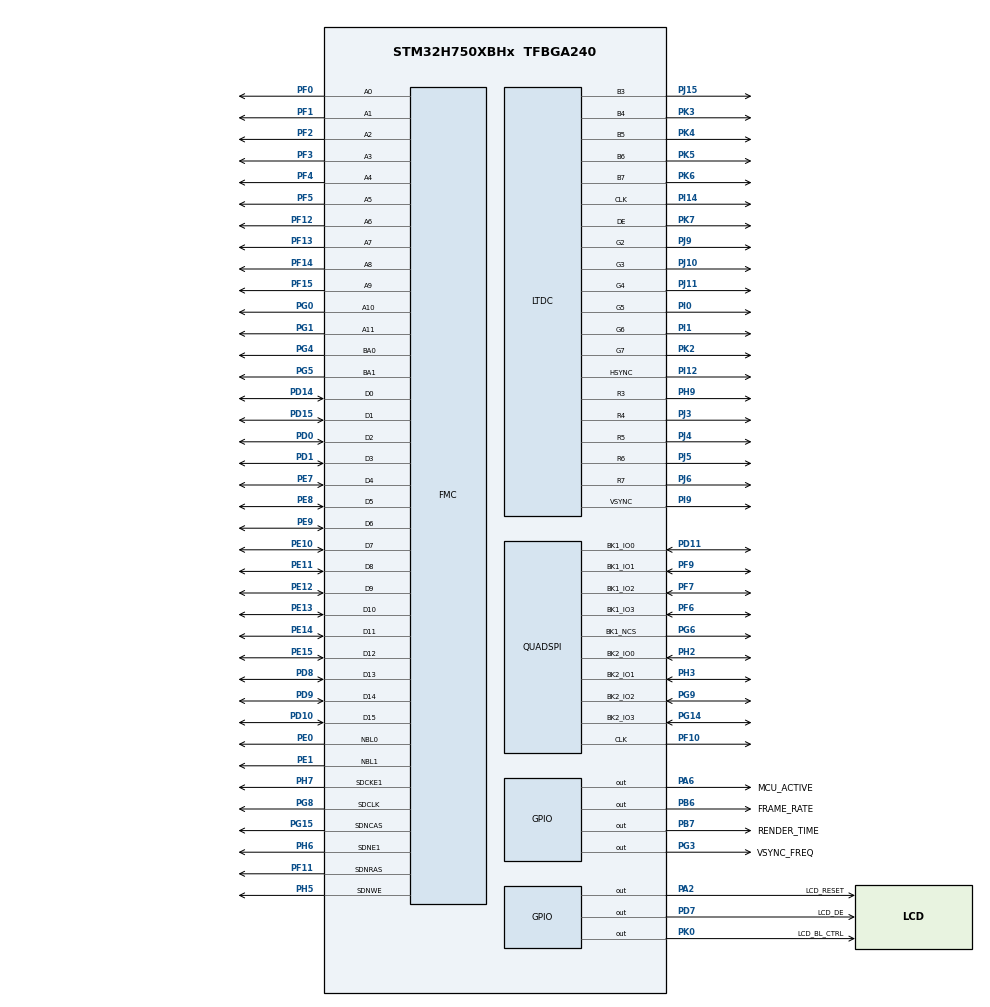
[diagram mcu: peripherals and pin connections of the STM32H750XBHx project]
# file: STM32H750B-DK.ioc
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CORTEX_M7.AccessPermission-Cortex_Memory_Protection_Unit_Region0_Settings=MPU_REGION_FULL_ACCESS
CORTEX_M7.AccessPermission-Cortex_Memory_Protection_Unit_Region1_Settings=MPU_REGION_NO_ACCESS
CORTEX_M7.AccessPermission-Cortex_Memory_Protection_Unit_Region2_Settings=MPU_REGION_FULL_ACCESS
CORTEX_M7.AccessPermission-Cortex_Memory_Protection_Unit_Region4_Settings=MPU_REGION_FULL_ACCESS
CORTEX_M7.BaseAddress-Cortex_Memory_Protection_Unit_Region0_Settings=0x24000000
CORTEX_M7.BaseAddress-Cortex_Memory_Protection_Unit_Region1_Settings=0x90000000
CORTEX_M7.BaseAddress-Cortex_Memory_Protection_Unit_Region2_Settings=0x90000000
CORTEX_M7.BaseAddress-Cortex_Memory_Protection_Unit_Region3_Settings=0xD0000000
CORTEX_M7.BaseAddress-Cortex_Memory_Protection_Unit_Region4_Settings=0xD0000000
CORTEX_M7.CPU_DCache=Enabled
CORTEX_M7.CPU_ICache=Enabled
CORTEX_M7.DisableExec-Cortex_Memory_Protection_Unit_Region0_Settings=MPU_INSTRUCTION_ACCESS_DISABLE
CORTEX_M7.DisableExec-Cortex_Memory_Protection_Unit_Region1_Settings=MPU_INSTRUCTION_ACCESS_DISABLE
CORTEX_M7.DisableExec-Cortex_Memory_Protection_Unit_Region2_Settings=MPU_INSTRUCTION_ACCESS_ENABLE
CORTEX_M7.DisableExec-Cortex_Memory_Protection_Unit_Region3_Settings=MPU_INSTRUCTION_ACCESS_DISABLE
CORTEX_M7.DisableExec-Cortex_Memory_Protection_Unit_Region4_Settings=MPU_INSTRUCTION_ACCESS_DISABLE
CORTEX_M7.Enable-Cortex_Memory_Protection_Unit_Region0_Settings=MPU_REGION_ENABLE
CORTEX_M7.Enable-Cortex_Memory_Protection_Unit_Region1_Settings=MPU_REGION_ENABLE
CORTEX_M7.Enable-Cortex_Memory_Protection_Unit_Region2_Settings=MPU_REGION_ENABLE
CORTEX_M7.Enable-Cortex_Memory_Protection_Unit_Region3_Settings=MPU_REGION_ENABLE
CORTEX_M7.Enable-Cortex_Memory_Protection_Unit_Region4_Settings=MPU_REGION_ENABLE
CORTEX_M7.IsBufferable-Cortex_Memory_Protection_Unit_Region0_Settings=MPU_ACCESS_BUFFERABLE
CORTEX_M7.IsBufferable-Cortex_Memory_Protection_Unit_Region1_Settings=MPU_ACCESS_NOT_BUFFERABLE
CORTEX_M7.IsBufferable-Cortex_Memory_Protection_Unit_Region2_Settings=MPU_ACCESS_BUFFERABLE
CORTEX_M7.IsCacheable-Cortex_Memory_Protection_Unit_Region0_Settings=MPU_ACCESS_CACHEABLE
CORTEX_M7.IsCacheable-Cortex_Memory_Protection_Unit_Region1_Settings=MPU_ACCESS_NOT_CACHEABLE
CORTEX_M7.IsCacheable-Cortex_Memory_Protection_Unit_Region2_Settings=MPU_ACCESS_CACHEABLE
CORTEX_M7.IsCacheable-Cortex_Memory_Protection_Unit_Region4_Settings=MPU_ACCESS_CACHEABLE
CORTEX_M7.IsShareable-Cortex_Memory_Protection_Unit_Region2_Settings=MPU_ACCESS_NOT_SHAREABLE
CORTEX_M7.IsShareable-Cortex_Memory_Protection_Unit_Region4_Settings=MPU_ACCESS_NOT_SHAREABLE
CORTEX_M7.MPU_Control=MPU_PRIVILEGED_DEFAULT
CORTEX_M7.Size-Cortex_Memory_Protection_Unit_Region0_Settings=MPU_REGION_SIZE_512KB
CORTEX_M7.Size-Cortex_Memory_Protection_Unit_Region1_Settings=MPU_REGION_SIZE_256MB
CORTEX_M7.Size-Cortex_Memory_Protection_Unit_Region2_Settings=MPU_REGION_SIZE_128MB
CORTEX_M7.Size-Cortex_Memory_Protection_Unit_Region3_Settings=MPU_REGION_SIZE_256MB
CORTEX_M7.Size-Cortex_Memory_Protection_Unit_Region4_Settings=MPU_REGION_SIZE_32MB
DMA2D.ColorMode=DMA2D_OUTPUT_RGB565
FMC.CASLatency2=FMC_SDRAM_CAS_LATENCY_3
FMC.ColumnBitsNumber2=FMC_SDRAM_COLUMN_BITS_NUM_8
FMC.ExitSelfRefreshDelay2=7
FMC.LoadToActiveDelay2=2
FMC.RCDDelay2=2
FMC.RPDelay2=2
FMC.ReadBurst2=FMC_SDRAM_RBURST_ENABLE
FMC.RowCycleDelay2=7
FMC.SDClockPeriod2=FMC_SDRAM_CLOCK_PERIOD_2
FMC.SelfRefreshTime2=4
FMC.WriteRecoveryTime2=5
FREERTOS.HEAP_NUMBER=4
FREERTOS.Tasks01=defaultTask,24,128,StartDefaultTask,Default,NULL,Dynamic,NULL,NULL;GUITask,24,8192,TouchGFX_Task,As external,NULL,Dynamic,NULL,NULL;videoTask,8,1000,videoTaskFunc,As external,NULL,Dynamic,NULL,NULL
FREERTOS.configTOTAL_HEAP_SIZE=100000
FREERTOS.configUSE_APPLICATION_TASK_TAG=1
FREERTOS.configUSE_IDLE_HOOK=1
FREERTOS.configUSE_MALLOC_FAILED_HOOK=0
JPEG.JPEG_RGB_FORMAT=JPEG_RGB565
LIBJPEG.RGB_ORDERING=BGR
LTDC.ActiveH=272
LTDC.ActiveW=480
LTDC.Alpha_L0=255
LTDC.BlendingFactor1_L0=LTDC_BLENDING_FACTOR1_CA
LTDC.BlendingFactor2_L0=LTDC_BLENDING_FACTOR2_CA
LTDC.HBP=3
LTDC.HSync=40
LTDC.ImageHeight_L0=272
LTDC.ImageWidth_L0=480
LTDC.Layers=0
LTDC.PixelFormat_L0=LTDC_PIXEL_FORMAT_RGB565
LTDC.VBP=3
LTDC.VSync=9
LTDC.WindowX1_L0=480
LTDC.WindowY1_L0=272
Mcu.Family=STM32H7
Mcu.Name=STM32H750XBHx
Mcu.Package=TFBGA240
Mdma.MDMA_Channel6.JPEG_OUTFIFO_TH.0.BlockCount=0
Mdma.MDMA_Channel6.JPEG_OUTFIFO_TH.0.BlockDataLength=0
Mdma.MDMA_Channel6.JPEG_OUTFIFO_TH.0.BufferTransferLength=32
Mdma.MDMA_Channel6.JPEG_OUTFIFO_TH.0.CircularMode=MDMA_LINEAR_LIST
Mdma.MDMA_Channel6.JPEG_OUTFIFO_TH.0.DataAlignment=MDMA_DATAALIGN_PACKENABLE
Mdma.MDMA_Channel6.JPEG_OUTFIFO_TH.0.DestBlockAddressOffset=0
Mdma.MDMA_Channel6.JPEG_OUTFIFO_TH.0.DestBurst=MDMA_DEST_BURST_32BEATS
Mdma.MDMA_Channel6.JPEG_OUTFIFO_TH.0.DestDataSize=MDMA_DEST_DATASIZE_BYTE
Mdma.MDMA_Channel6.JPEG_OUTFIFO_TH.0.DestinationInc=MDMA_DEST_INC_BYTE
Mdma.MDMA_Channel6.JPEG_OUTFIFO_TH.0.DstAddress=0
Mdma.MDMA_Channel6.JPEG_OUTFIFO_TH.0.Endianness=MDMA_LITTLE_ENDIANNESS_PRESERVE
Mdma.MDMA_Channel6.JPEG_OUTFIFO_TH.0.Instance=MDMA_Channel6
Mdma.MDMA_Channel6.JPEG_OUTFIFO_TH.0.MaskAddress=0
Mdma.MDMA_Channel6.JPEG_OUTFIFO_TH.0.MaskData=0
Mdma.MDMA_Channel6.JPEG_OUTFIFO_TH.0.Priority=MDMA_PRIORITY_VERY_HIGH
Mdma.MDMA_Channel6.JPEG_OUTFIFO_TH.0.Rank=First
Mdma.MDMA_Channel6.JPEG_OUTFIFO_TH.0.SourceBlockAddressOffset=0
Mdma.MDMA_Channel6.JPEG_OUTFIFO_TH.0.SourceBurst=MDMA_SOURCE_BURST_32BEATS
Mdma.MDMA_Channel6.JPEG_OUTFIFO_TH.0.SourceDataSize=MDMA_SRC_DATASIZE_WORD
Mdma.MDMA_Channel6.JPEG_OUTFIFO_TH.0.SourceInc=MDMA_SRC_INC_DISABLE
Mdma.MDMA_Channel6.JPEG_OUTFIFO_TH.0.SrcAddress=0
Mdma.MDMA_Channel6.JPEG_OUTFIFO_TH.0.TransferTriggerMode=MDMA_BUFFER_TRANSFER
Mdma.MDMA_Channel6.Request0=JPEG_OUTFIFO_TH
Mdma.MDMA_Channel6.RequestsNb=1
Mdma.MDMA_Channel7.JPEG_INFIFO_TH.0.BlockCount=0
Mdma.MDMA_Channel7.JPEG_INFIFO_TH.0.BlockDataLength=0
Mdma.MDMA_Channel7.JPEG_INFIFO_TH.0.BufferTransferLength=32
Mdma.MDMA_Channel7.JPEG_INFIFO_TH.0.CircularMode=MDMA_LINEAR_LIST
Mdma.MDMA_Channel7.JPEG_INFIFO_TH.0.DataAlignment=MDMA_DATAALIGN_PACKENABLE
Mdma.MDMA_Channel7.JPEG_INFIFO_TH.0.DestBlockAddressOffset=0
Mdma.MDMA_Channel7.JPEG_INFIFO_TH.0.DestBurst=MDMA_DEST_BURST_16BEATS
Mdma.MDMA_Channel7.JPEG_INFIFO_TH.0.DestDataSize=MDMA_DEST_DATASIZE_WORD
Mdma.MDMA_Channel7.JPEG_INFIFO_TH.0.DestinationInc=MDMA_DEST_INC_DISABLE
Mdma.MDMA_Channel7.JPEG_INFIFO_TH.0.DstAddress=0
Mdma.MDMA_Channel7.JPEG_INFIFO_TH.0.Endianness=MDMA_LITTLE_ENDIANNESS_PRESERVE
Mdma.MDMA_Channel7.JPEG_INFIFO_TH.0.Instance=MDMA_Channel7
Mdma.MDMA_Channel7.JPEG_INFIFO_TH.0.MaskAddress=0
Mdma.MDMA_Channel7.JPEG_INFIFO_TH.0.MaskData=0
Mdma.MDMA_Channel7.JPEG_INFIFO_TH.0.Priority=MDMA_PRIORITY_HIGH
Mdma.MDMA_Channel7.JPEG_INFIFO_TH.0.Rank=First
Mdma.MDMA_Channel7.JPEG_INFIFO_TH.0.SourceBlockAddressOffset=0
Mdma.MDMA_Channel7.JPEG_INFIFO_TH.0.SourceBurst=MDMA_SOURCE_BURST_32BEATS
Mdma.MDMA_Channel7.JPEG_INFIFO_TH.0.SourceDataSize=MDMA_SRC_DATASIZE_BYTE
Mdma.MDMA_Channel7.JPEG_INFIFO_TH.0.SourceInc=MDMA_SRC_INC_BYTE
Mdma.MDMA_Channel7.JPEG_INFIFO_TH.0.SrcAddress=0
Mdma.MDMA_Channel7.JPEG_INFIFO_TH.0.TransferTriggerMode=MDMA_BUFFER_TRANSFER
Mdma.MDMA_Channel7.Request0=JPEG_INFIFO_TH
Mdma.MDMA_Channel7.RequestsNb=1
Mdma.RequestSet0=MDMA_Channel7
Mdma.RequestSet1=MDMA_Channel6
Mdma.RequestSetsNb=2
NVIC.DMA2D_IRQn=true\:5\:0\:true\:false\:true\:false\:true\:true\:true
NVIC.JPEG_IRQn=true\:5\:0\:false\:false\:true\:true\:true\:true\:true
NVIC.LTDC_IRQn=true\:5\:0\:true\:false\:true\:false\:true\:true\:true
NVIC.MDMA_IRQn=true\:5\:0\:false\:false\:true\:true\:false\:true\:true
NVIC.PriorityGroup=NVIC_PRIORITYGROUP_4
NVIC.TIM6_DAC_IRQn=true\:0\:0\:false\:false\:true\:false\:false\:true\:true
NVIC.TimeBase=TIM6_DAC_IRQn
NVIC.TimeBaseIP=TIM6
PA2.GPIO_Label=LCD_RESET
PA2.Signal=GPIO_Output
PA6.GPIO_Label=MCU_ACTIVE
PA6.GPIO_Speed=GPIO_SPEED_FREQ_VERY_HIGH
PA6.Signal=GPIO_Output
PB6.GPIO_Label=FRAME_RATE
PB6.GPIO_Speed=GPIO_SPEED_FREQ_VERY_HIGH
PB6.Signal=GPIO_Output
PB7.GPIO_Label=RENDER_TIME
PB7.GPIO_Speed=GPIO_SPEED_FREQ_VERY_HIGH
PB7.Signal=GPIO_Output
PD0.Signal=FMC_D2_DA2
PD1.Signal=FMC_D3_DA3
PD10.Signal=FMC_D15_DA15
PD11.GPIO_Speed=GPIO_SPEED_FREQ_VERY_HIGH
PD11.Mode=Dual_Bank
PD11.Signal=QUADSPI_BK1_IO0
PD14.Signal=FMC_D0_DA0
PD15.Signal=FMC_D1_DA1
PD7.GPIO_Label=LCD_DE
PD7.Signal=GPIO_Output
PD8.Signal=FMC_D13_DA13
PD9.Signal=FMC_D14_DA14
PE0.Signal=FMC_NBL0
PE1.Signal=FMC_NBL1
PE10.Signal=FMC_D7_DA7
PE11.Signal=FMC_D8_DA8
PE12.Signal=FMC_D9_DA9
PE13.Signal=FMC_D10_DA10
PE14.Signal=FMC_D11_DA11
PE15.Signal=FMC_D12_DA12
PE7.Signal=FMC_D4_DA4
PE8.Signal=FMC_D5_DA5
PE9.Signal=FMC_D6_DA6
PF0.Signal=FMC_A0
PF1.Signal=FMC_A1
PF10.GPIO_Speed=GPIO_SPEED_FREQ_VERY_HIGH
PF10.Mode=Dual_Bank
PF10.Signal=QUADSPI_CLK
PF11.Signal=FMC_SDNRAS
PF12.Signal=FMC_A6
PF13.Signal=FMC_A7
PF14.Signal=FMC_A8
PF15.Signal=FMC_A9
PF2.Signal=FMC_A2
PF3.Signal=FMC_A3
PF4.Signal=FMC_A4
PF5.Signal=FMC_A5
PF6.GPIO_Speed=GPIO_SPEED_FREQ_VERY_HIGH
PF6.Mode=Dual_Bank
PF6.Signal=QUADSPI_BK1_IO3
PF7.GPIO_Speed=GPIO_SPEED_FREQ_VERY_HIGH
PF7.Mode=Dual_Bank
PF7.Signal=QUADSPI_BK1_IO2
PF9.GPIO_Speed=GPIO_SPEED_FREQ_VERY_HIGH
PF9.Mode=Dual_Bank
PF9.Signal=QUADSPI_BK1_IO1
PG0.Signal=FMC_A10
PG1.Signal=FMC_A11
PG14.GPIO_Speed=GPIO_SPEED_FREQ_VERY_HIGH
PG14.Mode=Dual_Bank
PG14.Signal=QUADSPI_BK2_IO3
PG15.Signal=FMC_SDNCAS
PG3.GPIO_Label=VSYNC_FREQ
PG3.GPIO_Speed=GPIO_SPEED_FREQ_VERY_HIGH
PG3.Signal=GPIO_Output
PG4.Signal=FMC_A14_BA0
PG5.Signal=FMC_A15_BA1
PG6.GPIO_Speed=GPIO_SPEED_FREQ_VERY_HIGH
PG6.Mode=Enable Chip Select 1 for both banks
PG6.Signal=QUADSPI_BK1_NCS
PG8.Signal=FMC_SDCLK
PG9.GPIO_Speed=GPIO_SPEED_FREQ_VERY_HIGH
PG9.Mode=Dual_Bank
PG9.Signal=QUADSPI_BK2_IO2
PH0-OSC_IN\ (PH0).Mode=HSE-External-Oscillator
PH0-OSC_IN\ (PH0).Signal=RCC_OSC_IN
PH1-OSC_OUT\ (PH1).Mode=HSE-External-Oscillator
PH1-OSC_OUT\ (PH1).Signal=RCC_OSC_OUT
PH2.GPIO_Speed=GPIO_SPEED_FREQ_VERY_HIGH
PH2.Mode=Dual_Bank
PH2.Signal=QUADSPI_BK2_IO0
PH3.GPIO_Speed=GPIO_SPEED_FREQ_VERY_HIGH
PH3.Mode=Dual_Bank
PH3.Signal=QUADSPI_BK2_IO1
PH5.Signal=FMC_SDNWE
PH6.Mode=SdramChipSelect2_2
PH6.Signal=FMC_SDNE1
PH7.Mode=SdramChipSelect2_2
PH7.Signal=FMC_SDCKE1
PH9.GPIO_Speed=GPIO_SPEED_FREQ_HIGH
PH9.Mode=RGB565
PH9.Signal=LTDC_R3
PI0.GPIO_Speed=GPIO_SPEED_FREQ_HIGH
PI0.Mode=RGB565
PI0.Signal=LTDC_G5
PI1.GPIO_Speed=GPIO_SPEED_FREQ_HIGH
PI1.Mode=RGB565
PI1.Signal=LTDC_G6
PI12.GPIO_Speed=GPIO_SPEED_FREQ_HIGH
PI12.Mode=RGB565
PI12.Signal=LTDC_HSYNC
PI14.GPIO_Speed=GPIO_SPEED_FREQ_HIGH
PI14.Mode=RGB565
PI14.Signal=LTDC_CLK
PI15.GPIO_Speed=GPIO_SPEED_FREQ_HIGH
PI15.Signal=LTDC_R0
PI9.GPIO_Speed=GPIO_SPEED_FREQ_HIGH
PI9.Mode=RGB565
PI9.Signal=LTDC_VSYNC
PJ0.GPIO_Speed=GPIO_SPEED_FREQ_HIGH
PJ0.Signal=LTDC_R1
PJ1.GPIO_Speed=GPIO_SPEED_FREQ_HIGH
PJ1.Signal=LTDC_R2
PJ10.GPIO_Speed=GPIO_SPEED_FREQ_HIGH
PJ10.Mode=RGB565
PJ10.Signal=LTDC_G3
PJ11.GPIO_Speed=GPIO_SPEED_FREQ_HIGH
PJ11.Mode=RGB565
PJ11.Signal=LTDC_G4
PJ12.GPIO_Speed=GPIO_SPEED_FREQ_HIGH
PJ12.Signal=LTDC_B0
PJ13.GPIO_Speed=GPIO_SPEED_FREQ_HIGH
PJ13.Signal=LTDC_B1
PJ14.GPIO_Speed=GPIO_SPEED_FREQ_HIGH
PJ14.Signal=LTDC_B2
PJ15.GPIO_Speed=GPIO_SPEED_FREQ_HIGH
PJ15.Mode=RGB565
PJ15.Signal=LTDC_B3
PJ3.GPIO_Speed=GPIO_SPEED_FREQ_HIGH
PJ3.Mode=RGB565
PJ3.Signal=LTDC_R4
PJ4.GPIO_Speed=GPIO_SPEED_FREQ_HIGH
PJ4.Mode=RGB565
PJ4.Signal=LTDC_R5
PJ5.GPIO_Speed=GPIO_SPEED_FREQ_HIGH
PJ5.Mode=RGB565
PJ5.Signal=LTDC_R6
PJ6.GPIO_Speed=GPIO_SPEED_FREQ_HIGH
PJ6.Mode=RGB565
PJ6.Signal=LTDC_R7
PJ7.GPIO_Speed=GPIO_SPEED_FREQ_HIGH
PJ7.Signal=LTDC_G0
PJ8.GPIO_Speed=GPIO_SPEED_FREQ_HIGH
PJ8.Signal=LTDC_G1
PJ9.GPIO_Speed=GPIO_SPEED_FREQ_HIGH
PJ9.Mode=RGB565
PJ9.Signal=LTDC_G2
PK0.GPIO_Label=LCD_BL_CTRL
PK0.PinState=GPIO_PIN_SET
PK0.Signal=GPIO_Output
PK2.GPIO_Speed=GPIO_SPEED_FREQ_HIGH
PK2.Mode=RGB565
PK2.Signal=LTDC_G7
PK3.GPIO_Speed=GPIO_SPEED_FREQ_HIGH
PK3.Mode=RGB565
PK3.Signal=LTDC_B4
PK4.GPIO_Speed=GPIO_SPEED_FREQ_HIGH
PK4.Mode=RGB565
PK4.Signal=LTDC_B5
PK5.GPIO_Speed=GPIO_SPEED_FREQ_HIGH
PK5.Mode=RGB565
PK5.Signal=LTDC_B6
PK6.GPIO_Speed=GPIO_SPEED_FREQ_HIGH
PK6.Mode=RGB565
PK6.Signal=LTDC_B7
PK7.GPIO_Speed=GPIO_SPEED_FREQ_HIGH
PK7.Mode=RGB565
PK7.Signal=LTDC_DE
ProjectManager.HeapSize=0x1000
ProjectManager.StackSize=0x1000
ProjectManager.TargetToolchain=STM32CubeIDE
QUADSPI.ChipSelectHighTime=QSPI_CS_HIGH_TIME_4_CYCLE
QUADSPI.ClockMode=QSPI_CLOCK_MODE_0
QUADSPI.ClockPrescaler=3
QUADSPI.FlashSize=26
QUADSPI.SampleShifting=QSPI_SAMPLE_SHIFTING_NONE
RCC.ADCFreq_Value=50390625
RCC.APB1Freq_Value=100000000
RCC.APB2Freq_Value=100000000
RCC.APB3Freq_Value=100000000
RCC.APB4Freq_Value=100000000
RCC.CortexFreq_Value=400000000
RCC.D1PPRE=RCC_APB3_DIV2
RCC.D2PPRE1=RCC_APB1_DIV2
RCC.D2PPRE2=RCC_APB2_DIV2
RCC.D3PPRE=RCC_APB4_DIV2
RCC.DIVM1=5
RCC.DIVM3=5
RCC.DIVN1=160
RCC.DIVN3=160
RCC.DIVQ1=4
RCC.DIVR3=83
RCC.HCLKFreq_Value=200000000
RCC.HPRE=RCC_HCLK_DIV2
RCC.PLL3FRACN=0
RCC.PLLSourceVirtual=RCC_PLLSOURCE_HSE
RCC.SYSCLKFreq_VALUE=400000000
RCC.SYSCLKSource=RCC_SYSCLKSOURCE_PLLCLK
RCC.USBFreq_Value=200000000
SH.FMC_A0.0=FMC_A0,12b-sda2
SH.FMC_A1.0=FMC_A1,12b-sda2
SH.FMC_A10.0=FMC_A10,12b-sda2
SH.FMC_A11.0=FMC_A11,12b-sda2
SH.FMC_A14_BA0.0=FMC_BA0,FourSdramBanks2
SH.FMC_A15_BA1.0=FMC_BA1,FourSdramBanks2
SH.FMC_A2.0=FMC_A2,12b-sda2
SH.FMC_A3.0=FMC_A3,12b-sda2
SH.FMC_A4.0=FMC_A4,12b-sda2
SH.FMC_A5.0=FMC_A5,12b-sda2
SH.FMC_A6.0=FMC_A6,12b-sda2
SH.FMC_A7.0=FMC_A7,12b-sda2
SH.FMC_A8.0=FMC_A8,12b-sda2
SH.FMC_A9.0=FMC_A9,12b-sda2
SH.FMC_D0_DA0.0=FMC_D0,sd-16b-d2
SH.FMC_D10_DA10.0=FMC_D10,sd-16b-d2
SH.FMC_D11_DA11.0=FMC_D11,sd-16b-d2
SH.FMC_D12_DA12.0=FMC_D12,sd-16b-d2
SH.FMC_D13_DA13.0=FMC_D13,sd-16b-d2
SH.FMC_D14_DA14.0=FMC_D14,sd-16b-d2
SH.FMC_D15_DA15.0=FMC_D15,sd-16b-d2
SH.FMC_D1_DA1.0=FMC_D1,sd-16b-d2
SH.FMC_D2_DA2.0=FMC_D2,sd-16b-d2
SH.FMC_D3_DA3.0=FMC_D3,sd-16b-d2
SH.FMC_D4_DA4.0=FMC_D4,sd-16b-d2
SH.FMC_D5_DA5.0=FMC_D5,sd-16b-d2
SH.FMC_D6_DA6.0=FMC_D6,sd-16b-d2
SH.FMC_D7_DA7.0=FMC_D7,sd-16b-d2
SH.FMC_D8_DA8.0=FMC_D8,sd-16b-d2
SH.FMC_D9_DA9.0=FMC_D9,sd-16b-d2
SH.FMC_NBL0.0=FMC_NBL0,Sd2ByteEnable2
SH.FMC_NBL1.0=FMC_NBL1,Sd2ByteEnable2
SH.FMC_SDCLK.0=FMC_SDCLK,12b-sda2
SH.FMC_SDNCAS.0=FMC_SDNCAS,12b-sda2
SH.FMC_SDNRAS.0=FMC_SDNRAS,12b-sda2
SH.FMC_SDNWE.0=FMC_SDNWE,12b-sda2
STMicroelectronics.X-CUBE-TOUCHGFX.4.21.1.ApplicationCcGraphicsJjApplication=TouchGFXOoGenerator
STMicroelectronics.X-CUBE-TOUCHGFX.4.21.1.tgfx_address1=0xD0000000
STMicroelectronics.X-CUBE-TOUCHGFX.4.21.1.tgfx_address2=0xD003FC00
STMicroelectronics.X-CUBE-TOUCHGFX.4.21.1.tgfx_buffering_strategy=Double
STMicroelectronics.X-CUBE-TOUCHGFX.4.21.1.tgfx_display_interface=disp_ltdc
STMicroelectronics.X-CUBE-TOUCHGFX.4.21.1.tgfx_hardware_accelerator=dma_2d
STMicroelectronics.X-CUBE-TOUCHGFX.4.21.1.tgfx_location=Allocate
STMicroelectronics.X-CUBE-TOUCHGFX.4.21.1.tgfx_pixel_format=RGB565\:16
STMicroelectronics.X-CUBE-TOUCHGFX.4.21.1.tgfx_vector_rendering=Enabled
STMicroelectronics.X-CUBE-TOUCHGFX.4.21.1.tgfx_video=Hardware
STMicroelectronics.X-CUBE-TOUCHGFX.4.21.1.tgfx_video_height=288
STMicroelectronics.X-CUBE-TOUCHGFX.4.21.1.tgfx_video_strategy=1
STMicroelectronics.X-CUBE-TOUCHGFX.4.21.1.tgfx_video_width=480
STMicroelectronics.X-CUBE-TOUCHGFX.4.21.1.tgfx_vsync=vsync_ltdc
VP_CRC_VS_CRC.Mode=CRC_Activate
VP_DMA2D_VS_DMA2D.Mode=DMA2D_Activate
VP_FREERTOS_VS_CMSIS_V2.Mode=CMSIS_V2
VP_JPEG_VS_JPEG.Mode=JPEG_Activate
VP_LIBJPEG_VS_JPEGLIB.Mode=Enabled
VP_STMicroelectronics.X-CUBE-TOUCHGFX_VS_GraphicsJjApplication_4.21.1.Mode=GraphicsJjApplication
VP_SYS_VS_tim6.Mode=TIM6
board=custom

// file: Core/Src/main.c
/* USER CODE BEGIN Header */
/**
  ******************************************************************************
  * @file           : main.c
  * @brief          : Main program body
  ******************************************************************************
  * @attention
  *
  * <h2><center>&copy; Copyright (c) 2020 STMicroelectronics.
  * All rights reserved.</center></h2>
  *
  * This software component is licensed by ST under Ultimate Liberty license
  * SLA0044, the "License"; You may not use this file except in compliance with
  * the License. You may obtain a copy of the License at:
  *                             www.st.com/SLA0044
  *
  ******************************************************************************
  */
/* USER CODE END Header */
#include "main.h"
#include "cmsis_os.h"
#include "libjpeg.h"
#include "app_touchgfx.h"

/* USER CODE BEGIN Includes */
#include "stm32h750b_discovery_qspi.h"
#include "stm32h750b_discovery_sdram.h"
/* USER CODE END Includes */

CRC_HandleTypeDef hcrc;

DMA2D_HandleTypeDef hdma2d;

JPEG_HandleTypeDef hjpeg;
MDMA_HandleTypeDef hmdma_jpeg_infifo_th;
MDMA_HandleTypeDef hmdma_jpeg_outfifo_th;

LTDC_HandleTypeDef hltdc;

QSPI_HandleTypeDef hqspi;

SDRAM_HandleTypeDef hsdram2;

/* Definitions for defaultTask */
osThreadId_t defaultTaskHandle;
const osThreadAttr_t defaultTask_attributes = {
  .name = "defaultTask",
  .stack_size = 128 * 4,
  .priority = (osPriority_t) osPriorityNormal,
};
/* Definitions for GUITask */
osThreadId_t GUITaskHandle;
const osThreadAttr_t GUITask_attributes = {
  .name = "GUITask",
  .stack_size = 8192 * 4,
  .priority = (osPriority_t) osPriorityNormal,
};
/* Definitions for videoTask */
osThreadId_t videoTaskHandle;
const osThreadAttr_t videoTask_attributes = {
  .name = "videoTask",
  .stack_size = 1000 * 4,
  .priority = (osPriority_t) osPriorityLow,
};
/* USER CODE BEGIN PV */
TIM_HandleTypeDef htim15;
volatile uint16_t ocPeriod = 2100;

/* USER CODE END PV */

void SystemClock_Config(void);
static void MPU_Config(void);
static void MX_GPIO_Init(void);
static void MX_MDMA_Init(void);
static void MX_LTDC_Init(void);
static void MX_DMA2D_Init(void);
static void MX_QUADSPI_Init(void);
static void MX_FMC_Init(void);
static void MX_JPEG_Init(void);
static void MX_CRC_Init(void);
void StartDefaultTask(void *argument);
extern void TouchGFX_Task(void *argument);
extern void videoTaskFunc(void *argument);

/* USER CODE BEGIN PFP */
void InitTIM15_OC();

/* USER CODE END PFP */

int main(void)
{

  /* MPU Configuration--------------------------------------------------------*/
  MPU_Config();

  /* Enable I-Cache---------------------------------------------------------*/
  SCB_EnableICache();

  /* Enable D-Cache---------------------------------------------------------*/
  SCB_EnableDCache();

  /* MCU Configuration--------------------------------------------------------*/

  /* Reset of all peripherals, Initializes the Flash interface and the Systick. */
  HAL_Init();

  /* Configure the system clock */
  SystemClock_Config();

  /* USER CODE BEGIN SysInit */
  /* Explicit enabling interrupt to support debugging in CubeIDE when using external flash loader */
  __enable_irq();
  /* USER CODE END SysInit */

  /* Initialize all configured peripherals */
  MX_GPIO_Init();
  MX_MDMA_Init();
  MX_LTDC_Init();
  MX_DMA2D_Init();
  MX_FMC_Init();
  MX_LIBJPEG_Init();
  MX_JPEG_Init();
  MX_CRC_Init();
  MX_TouchGFX_Init();
  /* Call PreOsInit function */
  MX_TouchGFX_PreOSInit();
  /* USER CODE BEGIN 2 */
  InitTIM15_OC();
  /* USER CODE END 2 */

  /* Init scheduler */
  osKernelInitialize();

  /* Create the thread(s) */
  /* creation of defaultTask */
  defaultTaskHandle = osThreadNew(StartDefaultTask, NULL, &defaultTask_attributes);

  /* creation of GUITask */
  GUITaskHandle = osThreadNew(TouchGFX_Task, NULL, &GUITask_attributes);

  /* creation of videoTask */
  videoTaskHandle = osThreadNew(videoTaskFunc, NULL, &videoTask_attributes);

  /* Start scheduler */
  osKernelStart();
  /* We should never get here as control is now taken by the scheduler */
  /* Infinite loop */
  while (1)
  {

  }
}

void SystemClock_Config(void)
{
  RCC_OscInitTypeDef RCC_OscInitStruct = {0};
  RCC_ClkInitTypeDef RCC_ClkInitStruct = {0};

  /** Supply configuration update enable
  */
  HAL_PWREx_ConfigSupply(PWR_LDO_SUPPLY);

  /** Configure the main internal regulator output voltage
  */
  __HAL_PWR_VOLTAGESCALING_CONFIG(PWR_REGULATOR_VOLTAGE_SCALE1);

  while(!__HAL_PWR_GET_FLAG(PWR_FLAG_VOSRDY)) {}

  /** Initializes the RCC Oscillators according to the specified parameters
  * in the RCC_OscInitTypeDef structure.
  */
  RCC_OscInitStruct.OscillatorType = RCC_OSCILLATORTYPE_HSE;
  RCC_OscInitStruct.HSEState = RCC_HSE_ON;
  RCC_OscInitStruct.PLL.PLLState = RCC_PLL_ON;
  RCC_OscInitStruct.PLL.PLLSource = RCC_PLLSOURCE_HSE;
  RCC_OscInitStruct.PLL.PLLM = 5;
  RCC_OscInitStruct.PLL.PLLN = 160;
  RCC_OscInitStruct.PLL.PLLP = 2;
  RCC_OscInitStruct.PLL.PLLQ = 4;
  RCC_OscInitStruct.PLL.PLLR = 2;
  RCC_OscInitStruct.PLL.PLLRGE = RCC_PLL1VCIRANGE_2;
  RCC_OscInitStruct.PLL.PLLVCOSEL = RCC_PLL1VCOWIDE;
  RCC_OscInitStruct.PLL.PLLFRACN = 0;
  if (HAL_RCC_OscConfig(&RCC_OscInitStruct) != HAL_OK)
  {
    Error_Handler();
  }

  /** Initializes the CPU, AHB and APB buses clocks
  */
  RCC_ClkInitStruct.ClockType = RCC_CLOCKTYPE_HCLK|RCC_CLOCKTYPE_SYSCLK
                              |RCC_CLOCKTYPE_PCLK1|RCC_CLOCKTYPE_PCLK2
                              |RCC_CLOCKTYPE_D3PCLK1|RCC_CLOCKTYPE_D1PCLK1;
  RCC_ClkInitStruct.SYSCLKSource = RCC_SYSCLKSOURCE_PLLCLK;
  RCC_ClkInitStruct.SYSCLKDivider = RCC_SYSCLK_DIV1;
  RCC_ClkInitStruct.AHBCLKDivider = RCC_HCLK_DIV2;
  RCC_ClkInitStruct.APB3CLKDivider = RCC_APB3_DIV2;
  RCC_ClkInitStruct.APB1CLKDivider = RCC_APB1_DIV2;
  RCC_ClkInitStruct.APB2CLKDivider = RCC_APB2_DIV2;
  RCC_ClkInitStruct.APB4CLKDivider = RCC_APB4_DIV2;

  if (HAL_RCC_ClockConfig(&RCC_ClkInitStruct, FLASH_LATENCY_2) != HAL_OK)
  {
    Error_Handler();
  }
}

static void MX_CRC_Init(void)
{

  hcrc.Instance = CRC;
  hcrc.Init.DefaultPolynomialUse = DEFAULT_POLYNOMIAL_ENABLE;
  hcrc.Init.DefaultInitValueUse = DEFAULT_INIT_VALUE_ENABLE;
  hcrc.Init.InputDataInversionMode = CRC_INPUTDATA_INVERSION_NONE;
  hcrc.Init.OutputDataInversionMode = CRC_OUTPUTDATA_INVERSION_DISABLE;
  hcrc.InputDataFormat = CRC_INPUTDATA_FORMAT_BYTES;
  if (HAL_CRC_Init(&hcrc) != HAL_OK)
  {
    Error_Handler();
  }

}

static void MX_DMA2D_Init(void)
{

  hdma2d.Instance = DMA2D;
  hdma2d.Init.Mode = DMA2D_M2M;
  hdma2d.Init.ColorMode = DMA2D_OUTPUT_RGB565;
  hdma2d.Init.OutputOffset = 0;
  hdma2d.LayerCfg[1].InputOffset = 0;
  hdma2d.LayerCfg[1].InputColorMode = DMA2D_INPUT_RGB565;
  hdma2d.LayerCfg[1].AlphaMode = DMA2D_NO_MODIF_ALPHA;
  hdma2d.LayerCfg[1].InputAlpha = 0;
  hdma2d.LayerCfg[1].AlphaInverted = DMA2D_REGULAR_ALPHA;
  hdma2d.LayerCfg[1].RedBlueSwap = DMA2D_RB_REGULAR;
  hdma2d.LayerCfg[1].ChromaSubSampling = DMA2D_NO_CSS;
  if (HAL_DMA2D_Init(&hdma2d) != HAL_OK)
  {
    Error_Handler();
  }
  if (HAL_DMA2D_ConfigLayer(&hdma2d, 1) != HAL_OK)
  {
    Error_Handler();
  }

}

static void MX_JPEG_Init(void)
{

  hjpeg.Instance = JPEG;
  if (HAL_JPEG_Init(&hjpeg) != HAL_OK)
  {
    Error_Handler();
  }

}

static void MX_LTDC_Init(void)
{

  LTDC_LayerCfgTypeDef pLayerCfg = {0};

  hltdc.Instance = LTDC;
  hltdc.Init.HSPolarity = LTDC_HSPOLARITY_AL;
  hltdc.Init.VSPolarity = LTDC_VSPOLARITY_AL;
  hltdc.Init.DEPolarity = LTDC_DEPOLARITY_AL;
  hltdc.Init.PCPolarity = LTDC_PCPOLARITY_IPC;
  hltdc.Init.HorizontalSync = 39;
  hltdc.Init.VerticalSync = 8;
  hltdc.Init.AccumulatedHBP = 42;
  hltdc.Init.AccumulatedVBP = 11;
  hltdc.Init.AccumulatedActiveW = 522;
  hltdc.Init.AccumulatedActiveH = 283;
  hltdc.Init.TotalWidth = 528;
  hltdc.Init.TotalHeigh = 285;
  hltdc.Init.Backcolor.Blue = 0;
  hltdc.Init.Backcolor.Green = 0;
  hltdc.Init.Backcolor.Red = 0;
  if (HAL_LTDC_Init(&hltdc) != HAL_OK)
  {
    Error_Handler();
  }
  pLayerCfg.WindowX0 = 0;
  pLayerCfg.WindowX1 = 480;
  pLayerCfg.WindowY0 = 0;
  pLayerCfg.WindowY1 = 272;
  pLayerCfg.PixelFormat = LTDC_PIXEL_FORMAT_RGB565;
  pLayerCfg.Alpha = 255;
  pLayerCfg.Alpha0 = 0;
  pLayerCfg.BlendingFactor1 = LTDC_BLENDING_FACTOR1_CA;
  pLayerCfg.BlendingFactor2 = LTDC_BLENDING_FACTOR2_CA;
  pLayerCfg.FBStartAdress = 0;
  pLayerCfg.ImageWidth = 480;
  pLayerCfg.ImageHeight = 272;
  pLayerCfg.Backcolor.Blue = 0;
  pLayerCfg.Backcolor.Green = 0;
  pLayerCfg.Backcolor.Red = 0;
  if (HAL_LTDC_ConfigLayer(&hltdc, &pLayerCfg, 0) != HAL_OK)
  {
    Error_Handler();
  }

}

static void MX_QUADSPI_Init(void)
{

  /* USER CODE BEGIN QUADSPI_Init 0 */
  BSP_QSPI_Init_t qspi_initParams ;
  /* USER CODE END QUADSPI_Init 0 */

  /* QUADSPI parameter configuration*/
  hqspi.Instance = QUADSPI;
  hqspi.Init.ClockPrescaler = 3;
  hqspi.Init.FifoThreshold = 1;
  hqspi.Init.SampleShifting = QSPI_SAMPLE_SHIFTING_NONE;
  hqspi.Init.FlashSize = 26;
  hqspi.Init.ChipSelectHighTime = QSPI_CS_HIGH_TIME_4_CYCLE;
  hqspi.Init.ClockMode = QSPI_CLOCK_MODE_0;
  hqspi.Init.DualFlash = QSPI_DUALFLASH_ENABLE;
  if (HAL_QSPI_Init(&hqspi) != HAL_OK)
  {
    Error_Handler();
  }
  /* USER CODE BEGIN QUADSPI_Init 2 */
  qspi_initParams.InterfaceMode = MT25TL01G_QPI_MODE;
  qspi_initParams.TransferRate  = MT25TL01G_DTR_TRANSFER ;
  qspi_initParams.DualFlashMode = MT25TL01G_DUALFLASH_ENABLE;
  BSP_QSPI_DeInit(0);
  if (BSP_QSPI_Init(0, &qspi_initParams) != BSP_ERROR_NONE)
  {
    Error_Handler( );
  }
  if(BSP_QSPI_EnableMemoryMappedMode(0) != BSP_ERROR_NONE)
  {
    Error_Handler( );
  }
  /* USER CODE END QUADSPI_Init 2 */

}

/**
  * Enable MDMA controller clock
  */
static void MX_MDMA_Init(void)
{

  /* MDMA controller clock enable */
  __HAL_RCC_MDMA_CLK_ENABLE();
  /* Local variables */

  /* MDMA interrupt initialization */
  /* MDMA_IRQn interrupt configuration */
  HAL_NVIC_SetPriority(MDMA_IRQn, 5, 0);
  HAL_NVIC_EnableIRQ(MDMA_IRQn);

}

/* FMC initialization function */
static void MX_FMC_Init(void)
{

  FMC_SDRAM_TimingTypeDef SdramTiming = {0};

  /** Perform the SDRAM2 memory initialization sequence
  */
  hsdram2.Instance = FMC_SDRAM_DEVICE;
  /* hsdram2.Init */
  hsdram2.Init.SDBank = FMC_SDRAM_BANK2;
  hsdram2.Init.ColumnBitsNumber = FMC_SDRAM_COLUMN_BITS_NUM_8;
  hsdram2.Init.RowBitsNumber = FMC_SDRAM_ROW_BITS_NUM_12;
  hsdram2.Init.MemoryDataWidth = FMC_SDRAM_MEM_BUS_WIDTH_16;
  hsdram2.Init.InternalBankNumber = FMC_SDRAM_INTERN_BANKS_NUM_4;
  hsdram2.Init.CASLatency = FMC_SDRAM_CAS_LATENCY_3;
  hsdram2.Init.WriteProtection = FMC_SDRAM_WRITE_PROTECTION_DISABLE;
  hsdram2.Init.SDClockPeriod = FMC_SDRAM_CLOCK_PERIOD_2;
  hsdram2.Init.ReadBurst = FMC_SDRAM_RBURST_ENABLE;
  hsdram2.Init.ReadPipeDelay = FMC_SDRAM_RPIPE_DELAY_0;
  /* SdramTiming */
  SdramTiming.LoadToActiveDelay = 2;
  SdramTiming.ExitSelfRefreshDelay = 7;
  SdramTiming.SelfRefreshTime = 4;
  SdramTiming.RowCycleDelay = 7;
  SdramTiming.WriteRecoveryTime = 5;
  SdramTiming.RPDelay = 2;
  SdramTiming.RCDDelay = 2;

  if (HAL_SDRAM_Init(&hsdram2, &SdramTiming) != HAL_OK)
  {
    Error_Handler( );
  }

  /* USER CODE BEGIN FMC_Init 2 */
  BSP_SDRAM_DeInit(0);
  if(BSP_SDRAM_Init(0) != BSP_ERROR_NONE)
  {
    Error_Handler( );
  }
  /* USER CODE END FMC_Init 2 */
}

static void MX_GPIO_Init(void)
{
  GPIO_InitTypeDef GPIO_InitStruct = {0};
/* USER CODE BEGIN MX_GPIO_Init_1 */
  __HAL_RCC_GPIOC_CLK_ENABLE();
/* USER CODE END MX_GPIO_Init_1 */

  /* GPIO Ports Clock Enable */
  __HAL_RCC_GPIOK_CLK_ENABLE();
  __HAL_RCC_GPIOG_CLK_ENABLE();
  __HAL_RCC_GPIOI_CLK_ENABLE();
  __HAL_RCC_GPIOE_CLK_ENABLE();
  __HAL_RCC_GPIOB_CLK_ENABLE();
  __HAL_RCC_GPIOJ_CLK_ENABLE();
  __HAL_RCC_GPIOD_CLK_ENABLE();
  __HAL_RCC_GPIOF_CLK_ENABLE();
  __HAL_RCC_GPIOH_CLK_ENABLE();
  __HAL_RCC_GPIOA_CLK_ENABLE();

  /*Configure GPIO pin Output Level */
  HAL_GPIO_WritePin(GPIOB, FRAME_RATE_Pin|RENDER_TIME_Pin, GPIO_PIN_RESET);

  /*Configure GPIO pin Output Level */
  HAL_GPIO_WritePin(LCD_DE_GPIO_Port, LCD_DE_Pin, GPIO_PIN_RESET);

  /*Configure GPIO pin Output Level */
  HAL_GPIO_WritePin(VSYNC_FREQ_GPIO_Port, VSYNC_FREQ_Pin, GPIO_PIN_RESET);

  /*Configure GPIO pin Output Level */
  HAL_GPIO_WritePin(LCD_BL_CTRL_GPIO_Port, LCD_BL_CTRL_Pin, GPIO_PIN_SET);

  /*Configure GPIO pin Output Level */
  HAL_GPIO_WritePin(GPIOA, LCD_RESET_Pin|MCU_ACTIVE_Pin, GPIO_PIN_RESET);

  /*Configure GPIO pins : FRAME_RATE_Pin RENDER_TIME_Pin */
  GPIO_InitStruct.Pin = FRAME_RATE_Pin|RENDER_TIME_Pin;
  GPIO_InitStruct.Mode = GPIO_MODE_OUTPUT_PP;
  GPIO_InitStruct.Pull = GPIO_NOPULL;
  GPIO_InitStruct.Speed = GPIO_SPEED_FREQ_VERY_HIGH;
  HAL_GPIO_Init(GPIOB, &GPIO_InitStruct);

  /*Configure GPIO pin : LCD_DE_Pin */
  GPIO_InitStruct.Pin = LCD_DE_Pin;
  GPIO_InitStruct.Mode = GPIO_MODE_OUTPUT_PP;
  GPIO_InitStruct.Pull = GPIO_NOPULL;
  GPIO_InitStruct.Speed = GPIO_SPEED_FREQ_LOW;
  HAL_GPIO_Init(LCD_DE_GPIO_Port, &GPIO_InitStruct);

  /*Configure GPIO pin : VSYNC_FREQ_Pin */
  GPIO_InitStruct.Pin = VSYNC_FREQ_Pin;
  GPIO_InitStruct.Mode = GPIO_MODE_OUTPUT_PP;
  GPIO_InitStruct.Pull = GPIO_NOPULL;
  GPIO_InitStruct.Speed = GPIO_SPEED_FREQ_VERY_HIGH;
  HAL_GPIO_Init(VSYNC_FREQ_GPIO_Port, &GPIO_InitStruct);

  /*Configure GPIO pin : LCD_BL_CTRL_Pin */
  GPIO_InitStruct.Pin = LCD_BL_CTRL_Pin;
  GPIO_InitStruct.Mode = GPIO_MODE_OUTPUT_PP;
  GPIO_InitStruct.Pull = GPIO_NOPULL;
  GPIO_InitStruct.Speed = GPIO_SPEED_FREQ_LOW;
  HAL_GPIO_Init(LCD_BL_CTRL_GPIO_Port, &GPIO_InitStruct);

  /*Configure GPIO pin : LCD_RESET_Pin */
  GPIO_InitStruct.Pin = LCD_RESET_Pin;
  GPIO_InitStruct.Mode = GPIO_MODE_OUTPUT_PP;
  GPIO_InitStruct.Pull = GPIO_NOPULL;
  GPIO_InitStruct.Speed = GPIO_SPEED_FREQ_LOW;
  HAL_GPIO_Init(LCD_RESET_GPIO_Port, &GPIO_InitStruct);

  /*Configure GPIO pin : MCU_ACTIVE_Pin */
  GPIO_InitStruct.Pin = MCU_ACTIVE_Pin;
  GPIO_InitStruct.Mode = GPIO_MODE_OUTPUT_PP;
  GPIO_InitStruct.Pull = GPIO_NOPULL;
  GPIO_InitStruct.Speed = GPIO_SPEED_FREQ_VERY_HIGH;
  HAL_GPIO_Init(MCU_ACTIVE_GPIO_Port, &GPIO_InitStruct);

/* USER CODE BEGIN MX_GPIO_Init_2 */
  /*Configure GPIO pin Output Level */
    HAL_GPIO_WritePin(LED_RED_GPIO_Port, LED_RED_Pin, GPIO_PIN_RESET);

    /*Configure GPIO pin Output Level */
    HAL_GPIO_WritePin(LED_GREEN_GPIO_Port, LED_GREEN_Pin, GPIO_PIN_SET);

    /*Configure GPIO pin : PUSHBTN_Pin */
    GPIO_InitStruct.Pin = PUSHBTN_Pin;
    GPIO_InitStruct.Mode = GPIO_MODE_IT_RISING;
    GPIO_InitStruct.Pull = GPIO_NOPULL;
    HAL_GPIO_Init(PUSHBTN_GPIO_Port, &GPIO_InitStruct);

    /*Configure GPIO pin : LED_RED_Pin */
    GPIO_InitStruct.Pin = LED_RED_Pin;
    GPIO_InitStruct.Mode = GPIO_MODE_OUTPUT_PP;
    GPIO_InitStruct.Pull = GPIO_NOPULL;
    GPIO_InitStruct.Speed = GPIO_SPEED_FREQ_LOW;
    HAL_GPIO_Init(LED_RED_GPIO_Port, &GPIO_InitStruct);

    /*Configure GPIO pin : LED_GREEN_Pin */
    GPIO_InitStruct.Pin = LED_GREEN_Pin;
    GPIO_InitStruct.Mode = GPIO_MODE_OUTPUT_PP;
    GPIO_InitStruct.Pull = GPIO_NOPULL;
    GPIO_InitStruct.Speed = GPIO_SPEED_FREQ_LOW;
    HAL_GPIO_Init(LED_GREEN_GPIO_Port, &GPIO_InitStruct);

    /* EXTI interrupt init*/
    HAL_NVIC_SetPriority(EXTI15_10_IRQn, 5, 0);
    HAL_NVIC_EnableIRQ(EXTI15_10_IRQn);
/* USER CODE END MX_GPIO_Init_2 */
}

/* USER CODE BEGIN 4 */
void InitTIM15_OC(){
	__HAL_RCC_GPIOE_CLK_ENABLE();
	/**TIM15 GPIO Configuration
	PE6     ------> TIM15_CH2
	*/
	GPIO_InitTypeDef GPIO_InitStruct = {0};
	GPIO_InitStruct.Pin = GPIO_PIN_6;
	GPIO_InitStruct.Mode = GPIO_MODE_AF_PP;
    GPIO_InitStruct.Pull = GPIO_NOPULL;
	GPIO_InitStruct.Speed = GPIO_SPEED_FREQ_LOW;
	GPIO_InitStruct.Alternate = GPIO_AF4_TIM15;
	HAL_GPIO_Init(GPIOE, &GPIO_InitStruct);

	__HAL_RCC_TIM15_CLK_ENABLE();
	htim15.Instance = TIM15;
	htim15.Init.Prescaler = 64-1;
	htim15.Init.CounterMode = TIM_COUNTERMODE_UP;
	htim15.Init.Period = 5000-1;
	htim15.Init.RepetitionCounter = 0;
	htim15.Init.AutoReloadPreload = TIM_AUTORELOAD_PRELOAD_ENABLE;
	HAL_TIM_OC_Init(&htim15);

	TIM_OC_InitTypeDef sConfigOC = {0};
	sConfigOC.OCMode = TIM_OCMODE_TOGGLE;
	sConfigOC.Pulse = 50;		// vrednost v CCR
	sConfigOC.OCPolarity = TIM_OCPOLARITY_HIGH;
	sConfigOC.OCNPolarity = TIM_OCNPOLARITY_HIGH;
	sConfigOC.OCFastMode = TIM_OCFAST_DISABLE;
	sConfigOC.OCIdleState = TIM_OCIDLESTATE_RESET;
	sConfigOC.OCNIdleState = TIM_OCNIDLESTATE_RESET;
	HAL_TIM_OC_ConfigChannel(&htim15, &sConfigOC, TIM_CHANNEL_2);

	//HAL_TIM_OC_Start(&htim15, TIM_CHANNEL_2);

	HAL_TIM_OC_Start_IT(&htim15, TIM_CHANNEL_2);
}

void HAL_TIM_OC_MspInit(TIM_HandleTypeDef* htim){
  if(htim->Instance==TIM15)
  {
    /* Peripheral clock enable */
    __HAL_RCC_TIM15_CLK_ENABLE();
    /* TIM15 interrupt Init */
    HAL_NVIC_SetPriority(TIM15_IRQn, 15, 0);
    HAL_NVIC_EnableIRQ(TIM15_IRQn);
  }
}

void HAL_GPIO_EXTI_Callback(uint16_t GPIO_Pin){
	if (GPIO_Pin == PUSHBTN_Pin) {
		ocPeriod = ocPeriod - 50;
	}
	if (ocPeriod < 100) ocPeriod = 2000;
}

void HAL_TIM_OC_DelayElapsedCallback(TIM_HandleTypeDef* htim){
  uint16_t ccr;

  // check if TIM15 asserted the interrupt:
  if (htim->Instance == TIM15) {
	  // check if Channel 3 asserted the OC interrupt
	  if(htim->Channel == HAL_TIM_ACTIVE_CHANNEL_2){
	    // Read and update CCR1
	    ccr = htim->Instance->CCR2;
	    ccr = ccr + ocPeriod;
	    if (ccr >= htim->Instance->ARR) {
	    	htim->Instance->CCR2 = ccr - htim->Instance->ARR;
	    }
	    else htim->Instance->CCR2 = ccr;
	  }
  }
}

/* USER CODE END 4 */

void StartDefaultTask(void *argument)
{
  /* USER CODE BEGIN 5 */
  /* Infinite loop */
  for(;;)
  {
    osDelay(100);
  }
  /* USER CODE END 5 */
}

/* MPU Configuration */

void MPU_Config(void)
{
  MPU_Region_InitTypeDef MPU_InitStruct = {0};

  /* Disables the MPU */
  HAL_MPU_Disable();

  /** Initializes and configures the Region and the memory to be protected
  */
  MPU_InitStruct.Enable = MPU_REGION_ENABLE;
  MPU_InitStruct.Number = MPU_REGION_NUMBER0;
  MPU_InitStruct.BaseAddress = 0x24000000;
  MPU_InitStruct.Size = MPU_REGION_SIZE_512KB;
  MPU_InitStruct.SubRegionDisable = 0x0;
  MPU_InitStruct.TypeExtField = MPU_TEX_LEVEL0;
  MPU_InitStruct.AccessPermission = MPU_REGION_FULL_ACCESS;
  MPU_InitStruct.DisableExec = MPU_INSTRUCTION_ACCESS_DISABLE;
  MPU_InitStruct.IsShareable = MPU_ACCESS_NOT_SHAREABLE;
  MPU_InitStruct.IsCacheable = MPU_ACCESS_CACHEABLE;
  MPU_InitStruct.IsBufferable = MPU_ACCESS_BUFFERABLE;

  HAL_MPU_ConfigRegion(&MPU_InitStruct);

  /** Initializes and configures the Region and the memory to be protected
  */
  MPU_InitStruct.Number = MPU_REGION_NUMBER1;
  MPU_InitStruct.BaseAddress = 0x90000000;
  MPU_InitStruct.Size = MPU_REGION_SIZE_256MB;
  MPU_InitStruct.AccessPermission = MPU_REGION_NO_ACCESS;
  MPU_InitStruct.IsCacheable = MPU_ACCESS_NOT_CACHEABLE;
  MPU_InitStruct.IsBufferable = MPU_ACCESS_NOT_BUFFERABLE;

  HAL_MPU_ConfigRegion(&MPU_InitStruct);

  /** Initializes and configures the Region and the memory to be protected
  */
  MPU_InitStruct.Number = MPU_REGION_NUMBER2;
  MPU_InitStruct.Size = MPU_REGION_SIZE_128MB;
  MPU_InitStruct.AccessPermission = MPU_REGION_FULL_ACCESS;
  MPU_InitStruct.DisableExec = MPU_INSTRUCTION_ACCESS_ENABLE;
  MPU_InitStruct.IsCacheable = MPU_ACCESS_CACHEABLE;
  MPU_InitStruct.IsBufferable = MPU_ACCESS_BUFFERABLE;

  HAL_MPU_ConfigRegion(&MPU_InitStruct);

  /** Initializes and configures the Region and the memory to be protected
  */
  MPU_InitStruct.Number = MPU_REGION_NUMBER3;
  MPU_InitStruct.BaseAddress = 0xD0000000;
  MPU_InitStruct.Size = MPU_REGION_SIZE_256MB;
  MPU_InitStruct.AccessPermission = MPU_REGION_NO_ACCESS;
  MPU_InitStruct.DisableExec = MPU_INSTRUCTION_ACCESS_DISABLE;
  MPU_InitStruct.IsCacheable = MPU_ACCESS_NOT_CACHEABLE;
  MPU_InitStruct.IsBufferable = MPU_ACCESS_NOT_BUFFERABLE;

  HAL_MPU_ConfigRegion(&MPU_InitStruct);

  /** Initializes and configures the Region and the memory to be protected
  */
  MPU_InitStruct.Number = MPU_REGION_NUMBER4;
  MPU_InitStruct.Size = MPU_REGION_SIZE_32MB;
  MPU_InitStruct.AccessPermission = MPU_REGION_FULL_ACCESS;
  MPU_InitStruct.IsCacheable = MPU_ACCESS_CACHEABLE;

  HAL_MPU_ConfigRegion(&MPU_InitStruct);
  /* Enables the MPU */
  HAL_MPU_Enable(MPU_PRIVILEGED_DEFAULT);

}

void HAL_TIM_PeriodElapsedCallback(TIM_HandleTypeDef *htim)
{
  if (htim->Instance == TIM6) {
    HAL_IncTick();
  }
}

void Error_Handler(void)
{
}
